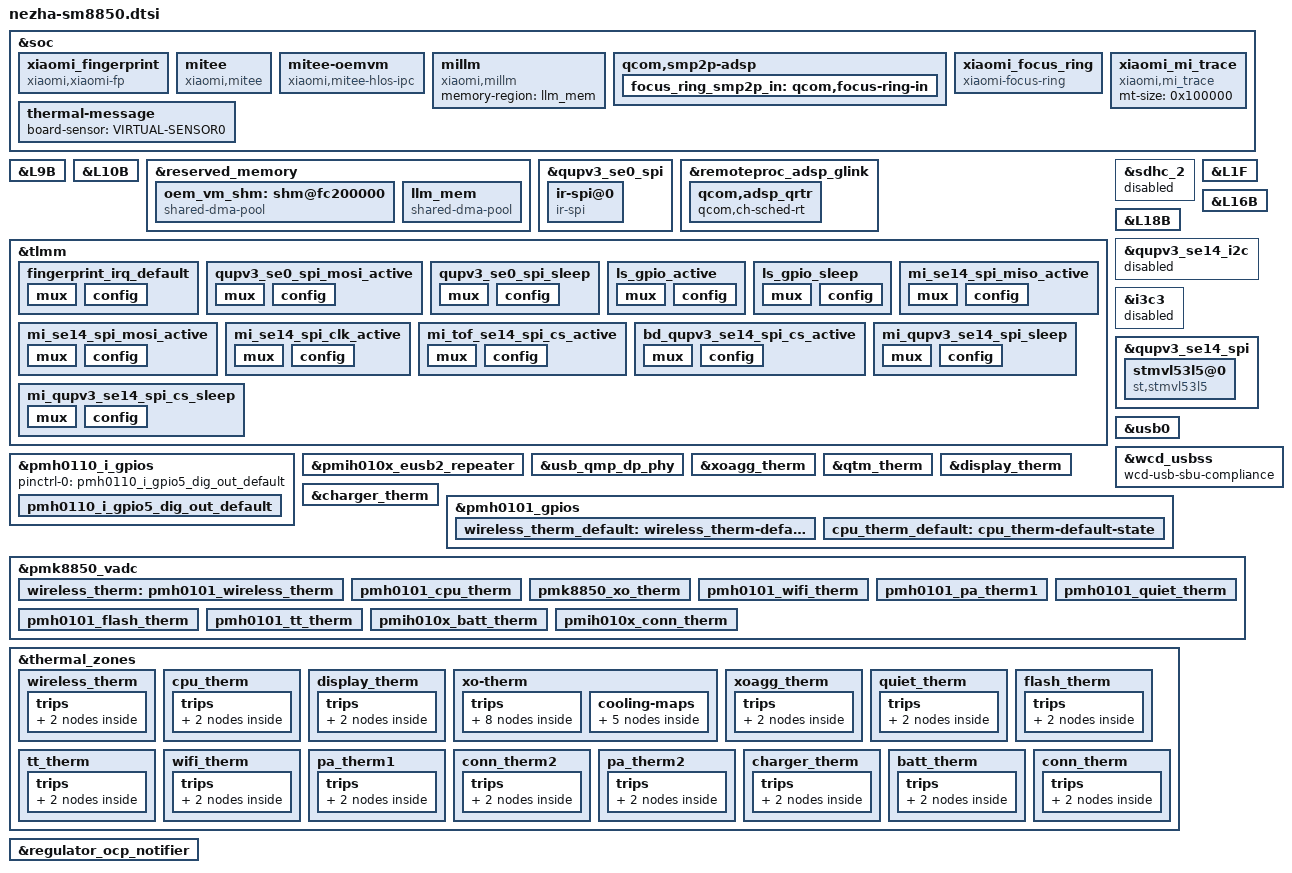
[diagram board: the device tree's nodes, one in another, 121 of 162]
/*
  this file is for attribution only of dada
  And public attribution of xiaomi platforms(like O2 O3)
*/

#include "sm8850-xiaomi-common.dtsi"
#include "nezha-beidou-common.dtsi"

&soc {
	xiaomi_fingerprint {
		compatible = "xiaomi,xiaomi-fp";
		xiaomi,gpio_irq = <&tlmm 99 0x0>;
		xiaomi,gpio_ipc = <&tlmm 99 0x0>;
		xiaomi,vendor_names = "P1_n2_132_431";
		intr2-pin-enable;
		intr2-side-config = "TIC";
		intr2-default-electrical = <1 1>;
		fp_3v3_vreg-supply = <&L9B>;
		fp_1v8_vreg-supply = <&L10B>;
		netlink-event = <25>;
		pinctrl-names = "irq_default";
		pinctrl-0 = <&fingerprint_irq_default>;
		status = "ok";
	};
};

&L9B {
	regulator-min-microvolt = <3300000>;
	regulator-max-microvolt = <3300000>;
	qcom,init-voltage = <3300000>;
};

&L10B {
	regulator-min-microvolt = <1800000>;
	regulator-max-microvolt = <1800000>;
	qcom,init-voltage = <1800000>;
};

/* mitee vm */
&reserved_memory {
//	oem_vm_mem: oem_vm_region@f7c00000 {
//		reg = <0x0 0xf7c00000 0x0 0x3800000>;
//	};
/* between is swiotlb */
	oem_vm_shm: shm@fc200000 {
		compatible = "shared-dma-pool";
		reusable;
		guarantee;
		alignment = <0x0 0x400000>;
		reg = <0x0 0xfc200000 0x0 0x400000>;
		gunyah-label = <0x3>;
	};
};

&soc {

	mitee: mitee {
		compatible = "xiaomi,mitee";
		binding-core = <4 5 6>;
		tui-supported;
	};

	mitee-oemvm {
		compatible = "xiaomi,mitee-hlos-ipc";
		xiaomi,master;
		gunyah-shm-label = <0x3>;
		peer-name = <0x4>;
		memory-region = <&oem_vm_shm>;
		dma-coherent;
	};
};
/* mitee vm */

/* millm cma */
&reserved_memory {
	llm_mem: llm_mem {
		compatible = "shared-dma-pool";
		reusable;
		guarantee;
		size = <0x0 0x0>;
	};
};

&soc {
	millm: millm {
		compatible = "xiaomi,millm";
		memory-region = <&llm_mem>;
	};
};
/* millm cma */

&qupv3_se0_spi {
	status = "ok";
	pinctrl-names = "default", "sleep";
	pinctrl-0 = <&qupv3_se0_spi_mosi_active>, <&ls_gpio_active>;
	pinctrl-1 = <&qupv3_se0_spi_sleep>, <&ls_gpio_sleep>;
	ir-spi@0 {
		compatible = "ir-spi";
		reg = <0>;
		spi-max-frequency = <19200000>;
		status = "ok";
	};
};

&remoteproc_adsp_glink {
	qcom,adsp_qrtr {
		qcom,ch-sched-rt;
	};
};

&tlmm {
	/* FP_INT_N */
	fingerprint_irq_default: fingerprint_irq_default {
		mux {
			pins = "gpio99";
			function = "gpio";
		};
		config {
			pins = "gpio99";
			drive-strength = <2>;
			bias-pull-down;
		};
	};

	qupv3_se0_spi_mosi_active: qupv3_se0_spi_mosi_active {
		mux {
			pins = "gpio83";
			function = "qup1_se0_l1";
		};

		config {
			pins = "gpio83";
			drive-strength = <6>;
			bias-disable;
		};
	};

	qupv3_se0_spi_sleep: qupv3_se0_spi_sleep {
		mux {
			pins = "gpio83";
			function = "gpio";
		};

		config {
			pins = "gpio83";
			drive-strength = <2>;
			bias-disable;
		};
	};

	ls_gpio_active: ls_gpio_active {
		mux {
			pins = "gpio159";
			function = "gpio";
		};

		config {
			pins = "gpio159";
			drive-strength = <2>;
			bias-disable;
			output-high;
		};
	};

	ls_gpio_sleep: ls_gpio_sleep {
		mux {
			pins = "gpio159";
			function = "gpio";
		};

		config {
			pins = "gpio159";
			drive-strength = <2>;
			bias-disable;
			output-high;
		};
	};
};

/* Mi_Focus_Ring */
&pmh0110_i_gpios {
	pinctrl-0 = <&pmh0110_i_gpio5_dig_out_default>;
	pinctrl-names = "default";
	pmh0110_i_gpio5_dig_out_default: pmh0110_i_gpio5_dig_out_default {
		pins = "gpio5";
		function = "normal";
		power-source = <2>; /* 1.2v */
		output-high;
		input-disable;
		bias-disable;
	};
};

&sdhc_2 {
	status = "disable";
	/delete-property/ cd-gpios;
};

&soc {
	qcom,smp2p-adsp{
		focus_ring_smp2p_in: qcom,focus-ring-in {
			qcom,entry-name = "mi_focus_ring";
			interrupt-controller;
			#interrupt-cells = <2>;
		};
	};

	xiaomi_focus_ring {
		compatible = "xiaomi-focus-ring";
		status = "ok";
		interrupts-extended = <&focus_ring_smp2p_in 0 0>,<&focus_ring_smp2p_in 1 0>,<&focus_ring_smp2p_in 2 0>,
		                      <&focus_ring_smp2p_in 3 0>,<&focus_ring_smp2p_in 4 0>,<&focus_ring_smp2p_in 5 0>,
		                      <&focus_ring_smp2p_in 6 0>,<&focus_ring_smp2p_in 7 0>,<&focus_ring_smp2p_in 8 0>;
		interrupt-names = "add_one_irq","add_two_irq","add_three_irq","sub_one_irq","sub_two_irq",
		                  "sub_three_irq","rotation_irq","motion_ping_irq","motion_pang_irq";
	};
};
/* Mi_Focus_Ring end*/

&tlmm {
	mi_se14_spi_miso_active: mi_se14_spi_miso_active {
		mux {
			pins = "gpio8";
			function = "qup3_se1_l0";
		};

		config {
			pins = "gpio8";
			drive-strength = <6>;
			bias-disable;
		};
	};

	mi_se14_spi_mosi_active: mi_se14_spi_mosi_active {
		mux {
			pins = "gpio9";
			function = "qup3_se1_l1";
		};

		config {
			pins = "gpio9";
			drive-strength = <6>;
			bias-disable;
		};
	};

	mi_se14_spi_clk_active: mi_se14_spi_clk_active {
		mux {
			pins = "gpio10";
			function = "qup3_se1_l2";
		};

		config {
			pins = "gpio10";
			drive-strength = <6>;
			bias-disable;
		};
	};

	mi_tof_se14_spi_cs_active: mi_tof_se14_spi_cs_active{
		mux{
			pins = "gpio11";
			function = "qup3_se1_l3";
		};
		config{
			pins = "gpio11";
			drive-strength = <6>;
			bias-pull-down;
		};
	};

	bd_qupv3_se14_spi_cs_active: bd_qupv3_se14_spi_cs_active {
		mux {
			pins = "gpio13";
			function = "qup3_se1_l4";
		};

		config {
			pins = "gpio13";
			drive-strength = <6>;
			bias-pull-down;
		};
	};

	mi_qupv3_se14_spi_sleep: mi_qupv3_se14_spi_sleep {
		mux {
			pins = "gpio8", "gpio9",
				"gpio10";
			function = "gpio";
		};

		config {
			pins = "gpio8", "gpio9",
				"gpio10";
			drive-strength = <2>;
			bias-pull-down;
		};
	};

	mi_qupv3_se14_spi_cs_sleep: mi_qupv3_se14_spi_cs_sleep {
		mux {
			pins = "gpio11","gpio13";
			function = "gpio";
		};

		config {
			pins = "gpio11","gpio13";
			drive-strength = <2>;
			bias-pull-up;
		};
	};
};

&L1F {
	regulator-min-microvolt = <1800000>;
	regulator-max-microvolt = <1800000>;
	qcom,init-voltage = <1800000>;
};

&L16B {
	regulator-min-microvolt = <3300000>;
	regulator-max-microvolt = <3300000>;
	qcom,init-voltage = <3300000>;
};

&L18B {
	regulator-min-microvolt = <1200000>;
	regulator-max-microvolt = <1200000>;
	qcom,init-voltage = <1200000>;
};

&qupv3_se14_i2c{
	status = "disabled";
};
&i3c3 {
	status = "disabled";
};

&qupv3_se14_spi {
	status = "ok";
	pinctrl-0 = <&mi_se14_spi_miso_active>, <&mi_se14_spi_mosi_active>, <&mi_se14_spi_clk_active>, <&mi_tof_se14_spi_cs_active>, <&bd_qupv3_se14_spi_cs_active>;
	pinctrl-1 = <&mi_qupv3_se14_spi_sleep>,  <&mi_qupv3_se14_spi_cs_sleep>;
	stmvl53l5@0 {
		compatible = "st,stmvl53l5";
		reg = <0>;
		_1P8_power-supply = <&L1F>;
		_3P0_power-supply = <&L16B>;
		_1P2_power-supply = <&L18B>;
		spi-max-frequency = <3000000>;
		stm,l8_firmware_name = "stmvl53l8.bin";
		stm,l5_firmware_name = "stmvl53l5.bin";
		status = "ok";
	};
};

&usb0 {
	qcom,wcd_usbss = <&wcd_usbss>;
	wcd_equ = <0xF8>;
	wcd_equ_host = <0xC0>;
};

&wcd_usbss {
	wcd-usb-sbu-compliance;
};

&pmih010x_eusb2_repeater {
	qcom,host-param-override-seq =
		<0x00 0x50
		0x0E 0x51
		0x04 0x52
		0x07 0x53
		0x05 0x54
		0x03 0x55
		0x03 0x56
		0x03 0x57
		0x02 0x58
		0x03 0x59
		0x03 0x5a
		0x02 0x5b>;
	qcom,param-override-seq =
		<0x00 0x50
		0x0E 0x51
		0x01 0x52
		0x07 0x53
		0x03 0x54
		0x00 0x55
		0x00 0x56
		0x06 0x57
		0x02 0x58
		0x03 0x59
		0x01 0x5a
		0x02 0x5b>;
};

&usb_qmp_dp_phy {
	usb3,eyegram-tuning;
	qcom,usb3-phy-eye-seq =
	/* <reg_offset, value>*/
		<USB3_DP_PCS_G12S1_TXMGN_V0 0x1F
			USB3_DP_PCS_G12S1_TXDEEMPH_M3P5DB 0x17>;
	qcom,host-usb3-phy-eye-seq =
		<USB3_DP_PCS_G12S1_TXMGN_V0 0x1F
			USB3_DP_PCS_G12S1_TXDEEMPH_M3P5DB 0x16>;
};

&xoagg_therm {
	status = "ok";
};

&qtm_therm {
	status = "ok";
};

&display_therm {
	status = "ok";
};

&charger_therm {
	status = "ok";
};

&pmh0101_gpios {
	pinctrl-0 = <&wireless_therm_default>, <&cpu_therm_default>;
	pinctrl-names = "default";

	wireless_therm_default: wireless_therm-default-state {
		pins = "gpio9";
		function = "normal";
		bias-high-impedance;
	};

	cpu_therm_default: cpu_therm-default-state {
		pins = "gpio12";
		function = "normal";
		bias-high-impedance;
	};
};

/*&pmih010x_gpios {
	pinctrl-0 = <&display_therm_default>, <&charger_therm_default>;
	pinctrl-names = "default";

	display_therm_default: display_therm-default-state {
		pins = "gpio18";
		function = "normal";
		bias-high-impedance;
	};

	charger_therm_default: charger_therm-default-state {
		pins = "gpio12";
		function = "normal";
		bias-high-impedance;
	};
};*/

&pmk8850_vadc {
	pinctrl-0 = <&xoagg_therm_default>, <&pa_therm2_default>, <&qtm_therm_default>;
	pinctrl-names = "default";

	/* PMH0101 ADC Channels */
	wireless_therm: pmh0101_wireless_therm {
		reg = <PMH0101_ADC5_GEN4_AMUX3_GPIO9_100K_PU(0, PMH0101_SID)>;
		label = "pmh0101_wireless_therm";
		qcom,ratiometric;
		qcom,hw-settle-time = <200>;
		qcom,adc-tm-type = <1>;
	};

	pmh0101_cpu_therm {
		reg = <PMH0101_ADC5_GEN4_AMUX4_GPIO12_100K_PU(0, PMH0101_SID)>;
		label = "pmh0101_cpu_therm";
		qcom,ratiometric;
		qcom,hw-settle-time = <200>;
		qcom,adc-tm-type = <1>;
	};

	/* PMIH010X ADC Channels */
	/*pmih010x_display_therm {
		reg = <PMIH010X_ADC5_GEN4_AMUX5_GPIO18_100K_PU(1, PMIH010X_SID)>;
		label = "pmih010x_display_therm";
		qcom,ratiometric;
		qcom,hw-settle-time = <200>;
		qcom,pre-scaling = <1 1>;
		qcom,adc-tm-type = <1>;
		qcom,adc5-gen4;
	};*/

	pmk8850_xo_therm {
		reg = <PMK8850_ADC5_GEN4_AMUX_THM1_XO_THERM_100K_PU(0, PMK8850_SID)>;
		label = "pmk8850_xo_therm";
		qcom,ratiometric;
		qcom,hw-settle-time = <200>;
		qcom,adc-tm-type = <1>;
	};

	pmh0101_wifi_therm {
		reg = <PMH0101_ADC5_GEN4_AMUX_THM3_100K_PU(0, PMH0101_SID)>;
		label = "pmh0101_wifi_therm";
		qcom,ratiometric;
		qcom,hw-settle-time = <200>;
		qcom,adc-tm-type = <1>;
	};

	pmh0101_pa_therm1 {
		reg = <PMH0101_ADC5_GEN4_AMUX_THM4_100K_PU(0, PMH0101_SID)>;
		label = "pmh0101_pa_therm_1";
		qcom,ratiometric;
		qcom,hw-settle-time = <200>;
		qcom,adc-tm-type = <1>;
	};

	pmh0101_quiet_therm {
		reg = <PMH0101_ADC5_GEN4_AMUX_THM1_100K_PU(0, PMH0101_SID)>;
		label = "pmh0101_quiet_therm";
		qcom,ratiometric;
		qcom,hw-settle-time = <200>;
		qcom,adc-tm-type = <1>;
	};

	pmh0101_flash_therm {
		reg = <PMH0101_ADC5_GEN4_AMUX_THM2_100K_PU(0, PMH0101_SID)>;
		label = "pmh0101_flash_therm";
		qcom,ratiometric;
		qcom,hw-settle-time = <200>;
		qcom,adc-tm-type = <1>;
	};

	pmh0101_tt_therm {
		reg = < PMH0101_ADC5_GEN4_AMUX_THM5_100K_PU(0, PMH0101_SID)>;
		label = "pmh0101_tt_therm";
		qcom,ratiometric;
		qcom,hw-settle-time = <200>;
		qcom,adc-tm-type = <1>;
	};

	pmih010x_batt_therm {
		reg = <PMIH010X_ADC5_GEN4_AMUX_THM1_BAT_THERM_100K_PU(1, PMIH010X_SID)>;
		label = "pmih010x_batt_therm";
		qcom,ratiometric;
		qcom,hw-settle-time = <200>;
		qcom,adc-tm-type = <1>;
	};

	pmih010x_conn_therm {
		reg = <PMIH010X_ADC5_GEN4_AMUX_THM4_USB_THERM_100K_PU(1, PMIH010X_SID)>;
		label = "pmih010x_conn_therm_1";
		qcom,ratiometric;
		qcom,hw-settle-time = <200>;
		qcom,adc-tm-type = <1>;
	};

	/*pmih010x_charger_therm {
		reg = <PMIH010X_ADC5_GEN4_AMUX4_GPIO12_100K_PU(1, PMIH010X_SID)>;
		label = "pmih010x_charger_therm";
		qcom,ratiometric;
		qcom,hw-settle-time = <200>;
		qcom,pre-scaling = <1 1>;
		qcom,adc-tm-type = <1>;
		qcom,adc5-gen4;
	};*/
};

&thermal_zones {
	/* WIRELESS_THERM */
	wireless_therm {
		thermal-sensors = <&pmk8850_vadc
				   PMH0101_ADC5_GEN4_AMUX3_GPIO9_100K_PU(0, PMH0101_SID)>;

		trips {
			active-config0 {
				temperature = <125000>;
				hysteresis = <1000>;
				type = "passive";
			};

			active-config1 {
				temperature = <125000>;
				hysteresis = <1000>;
				type = "passive";
			};
		};
	};

	/* CPU_THERM */
	cpu_therm {
		thermal-sensors = <&pmk8850_vadc
				   PMH0101_ADC5_GEN4_AMUX4_GPIO12_100K_PU(0, PMH0101_SID)>;

		trips {
			active-config0 {
				temperature = <125000>;
				hysteresis = <1000>;
				type = "passive";
			};

			active-config1 {
				temperature = <125000>;
				hysteresis = <1000>;
				type = "passive";
			};
		};
	};

	/* DISPLAY_THERM */
	display_therm {
		thermal-sensors = <&pmk8850_vadc
				   PMIH010X_ADC5_GEN4_AMUX5_GPIO18_100K_PU(1, PMIH010X_SID)>;

		trips {
			active-config0 {
				temperature = <125000>;
				hysteresis = <1000>;
				type = "passive";
			};

			active-config1 {
				temperature = <125000>;
				hysteresis = <1000>;
				type = "passive";
			};
		};
	};

	/* XO_THERM */
	xo-therm {
		thermal-sensors = <&pmk8850_vadc
				   PMK8850_ADC5_GEN4_AMUX_THM1_XO_THERM_100K_PU(0, PMK8850_SID)>;

		trips {
			active-config0 {
				temperature = <125000>;
				hysteresis = <1000>;
				type = "passive";
			};

			active-config1 {
				temperature = <125000>;
				hysteresis = <1000>;
				type = "passive";
			};

			trip_config0: trip-config0 {
				temperature = <78000>;
				hysteresis = <8000>;
				type = "passive";
			};

			trip_config1: trip-config1 {
				temperature = <80000>;
				hysteresis = <10000>;
				type = "passive";
			};

			shutdown-trip {
				temperature = <90000>;
				hysteresis = <0>;
				type = "hot";
			};

			display_test_config1: display-test-config1 {
				temperature = <125000>;
				hysteresis = <1000>;
				type = "passive";
			};

			display_test_config2: display-test-config2 {
				temperature = <125000>;
				hysteresis = <1000>;
				type = "passive";
			};

			display_test_config3: display-test-config3 {
				temperature = <125000>;
				hysteresis = <1000>;
				type = "passive";
			};
		};

		cooling-maps {
			therm_cdev0 {
				trip = <&trip_config0>;
				cooling-device = <&APC1_MX_CX_PAUSE 1 1
					&APC0_MX_CX_PAUSE 1 1
					&cdsp_sw 5 THERMAL_NO_LIMIT
					&msm_gpu 5 THERMAL_NO_LIMIT>;
			};

			therm_cdev1 {
				trip = <&trip_config1>;
				cooling-device = <&cpu3_hotplug 1 1
					&cpu4_hotplug 1 1
					&cpu5_hotplug 1 1
					&cpu6_hotplug 1 1
					&cpu7_hotplug 1 1
					&modem_lte_dsc 255 255
					&modem_nr_scg_dsc 255 255>;
			};

			display_cdev1 {
				trip = <&display_test_config1>;
				cooling-device = <&display_fps 1 1>;
			};

			display_cdev2 {
				trip = <&display_test_config2>;
				cooling-device = <&display_fps 2 2>;
			};

			display_cdev3 {
				trip = <&display_test_config3>;
				cooling-device = <&display_fps 3 3>;
			};
		};
	};

	/* XOAGG_THERM */
	xoagg_therm {
		thermal-sensors = <&pmk8850_vadc
				   PMK8850_ADC5_GEN4_AMUX2_GPIO7_100K_PU(0, PMK8850_SID)>;

		trips {
			active-config0 {
				temperature = <125000>;
				hysteresis = <1000>;
				type = "passive";
			};

			active-config1 {
				temperature = <125000>;
				hysteresis = <1000>;
				type = "passive";
			};
		};
	};

	/* SKIN_THERM */
	quiet_therm {
		thermal-sensors = <&pmk8850_vadc
				   PMH0101_ADC5_GEN4_AMUX_THM1_100K_PU(0, PMH0101_SID)>;

		trips {
			active-config0 {
				temperature = <125000>;
				hysteresis = <1000>;
				type = "passive";
			};

			active-config1 {
				temperature = <125000>;
				hysteresis = <1000>;
				type = "passive";
			};
		};
	};

	/* CAM_FLASH_THERM */
	flash_therm {
		thermal-sensors = <&pmk8850_vadc
				   PMH0101_ADC5_GEN4_AMUX_THM2_100K_PU(0, PMH0101_SID)>;

		trips {
			active-config0 {
				temperature = <125000>;
				hysteresis = <1000>;
				type = "passive";
			};

			active-config1 {
				temperature = <125000>;
				hysteresis = <1000>;
				type = "passive";
			};
		};
	};

	tt_therm {
		thermal-sensors = <&pmk8850_vadc
				   PMH0101_ADC5_GEN4_AMUX_THM5_100K_PU(0, PMH0101_SID)>;

		trips {
			active-config0 {
				temperature = <125000>;
				hysteresis = <1000>;
				type = "passive";
			};

			active-config1 {
				temperature = <125000>;
				hysteresis = <1000>;
				type = "passive";
			};
		};
	};

	/* WLAN_THERM */
	wifi_therm {
		thermal-sensors = <&pmk8850_vadc
				   PMH0101_ADC5_GEN4_AMUX_THM3_100K_PU(0, PMH0101_SID)>;

		trips {
			active-config0 {
				temperature = <125000>;
				hysteresis = <1000>;
				type = "passive";
			};

			active-config1 {
				temperature = <125000>;
				hysteresis = <1000>;
				type = "passive";
			};
		};
	};

	/* PA_THERM1 */
	pa_therm1 {
		thermal-sensors = <&pmk8850_vadc
				   PMH0101_ADC5_GEN4_AMUX_THM4_100K_PU(0, PMH0101_SID)>;

		trips {
			active-config0 {
				temperature = <125000>;
				hysteresis = <1000>;
				type = "passive";
			};

			active-config1 {
				temperature = <125000>;
				hysteresis = <1000>;
				type = "passive";
			};
		};
	};

	/* QTM_THERM */
	conn_therm2 {
		thermal-sensors = <&pmk8850_vadc
				   PMH0101_ADC5_GEN4_AMUX2_GPIO2_100K_PU(0, PMH0101_SID)>;

		trips {
			active-config0 {
				temperature = <125000>;
				hysteresis = <1000>;
				type = "passive";
			};

			active-config1 {
				temperature = <125000>;
				hysteresis = <1000>;
				type = "passive";
			};
		};
	};

	/* PA_THERM2 */
	pa_therm2 {
		thermal-sensors = <&pmk8850_vadc
				   PMH0101_ADC5_GEN4_AMUX_THM6_GPIO3_100K_PU(0, PMH0101_SID)>;

		trips {
			active-config0 {
				temperature = <125000>;
				hysteresis = <1000>;
				type = "passive";
			};

			active-config1 {
				temperature = <125000>;
				hysteresis = <1000>;
				type = "passive";
			};
		};
	};

	/* WLS_THERM */
	charger_therm {
		thermal-sensors = <&pmk8850_vadc
				   PMIH010X_ADC5_GEN4_AMUX4_GPIO12_100K_PU(1, PMIH010X_SID)>;

		trips {
			active-config0 {
				temperature = <125000>;
				hysteresis = <1000>;
				type = "passive";
			};

			active-config1 {
				temperature = <125000>;
				hysteresis = <1000>;
				type = "passive";
			};
		};
	};

	/* BATT_THERM */
	batt_therm {
		thermal-sensors = <&pmk8850_vadc
				   PMIH010X_ADC5_GEN4_AMUX_THM1_BAT_THERM_100K_PU(1, PMIH010X_SID)>;

		trips {
			active-config0 {
				temperature = <125000>;
				hysteresis = <1000>;
				type = "passive";
			};

			active-config1 {
				temperature = <125000>;
				hysteresis = <1000>;
				type = "passive";
			};
		};
	};

	/* USB_THERM */
	conn_therm {
		thermal-sensors = <&pmk8850_vadc
				   PMIH010X_ADC5_GEN4_AMUX_THM4_USB_THERM_100K_PU(1, PMIH010X_SID)>;

		trips {
			active-config0 {
				temperature = <125000>;
				hysteresis = <1000>;
				type = "passive";
			};

			active-config1 {
				temperature = <125000>;
				hysteresis = <1000>;
				type = "passive";
			};
		};
	};

	/* BATT2_THERM */
	/*sys-therm-12 {
		thermal-sensors = <&pmk8850_vadc
				   PMIH010X_ADC5_GEN4_AMUX3_BAT2_THERM_100K_PU(1, PMIH010X_SID)>;

		trips {
			active-config0 {
				temperature = <125000>;
				hysteresis = <1000>;
				type = "passive";
			};

			active-config1 {
				temperature = <125000>;
				hysteresis = <1000>;
				type = "passive";
			};
		};
	};*/
};

/*Remove PM8010 N for hardware design*/
&regulator_ocp_notifier {
	/delete-property/ periph-d40-supply;
	/delete-property/ periph-d41-supply;
	/delete-property/ periph-d42-supply;
	/delete-property/ periph-d43-supply;
	/delete-property/ periph-d44-supply;
	/delete-property/ periph-d45-supply;
	/delete-property/ periph-d46-supply;
};

&soc {
 	thermal-message {
  		board-sensor = "VIRTUAL-SENSOR0";
 	};
 };

&soc {
	xiaomi_mi_trace {
		compatible = "xiaomi,mi_trace";
		mt-size = <0x100000>;
	};
 };
